VERSION "HINBNYYYYYYYYYYYYYYYYYYYYYYYYYYYNNNNNNNNNN/4/%%%/4/'%**4NNN///"

NS_ :

BS_:

BU_: EMV_Statusmeldungen

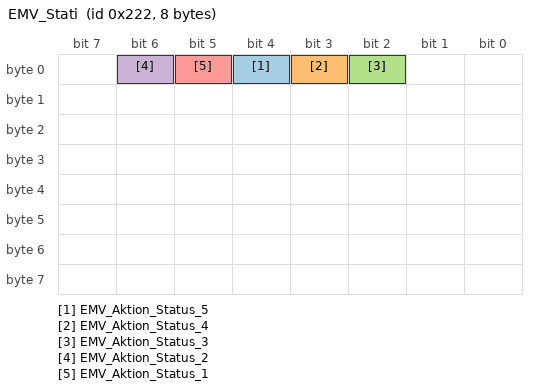
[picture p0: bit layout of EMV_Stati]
BO_ 546 EMV_Stati: 8 EMV_Statusmeldungen
 SG_ EMV_Aktion_Status_5 : 4|1@1+ (1,0) [0|1] "" Vector__XXX
 SG_ EMV_Aktion_Status_4 : 3|1@1+ (1,0) [0|1] "" Vector__XXX
 SG_ EMV_Aktion_Status_3 : 2|1@1+ (1,0) [0|1] ""  EMV_Statusmeldungen
 SG_ EMV_Aktion_Status_2 : 6|1@1+ (1,0) [0|1] "" Vector__XXX
 SG_ EMV_Aktion_Status_1 : 5|1@1+ (1,0) [0|1] "" Vector__XXX
